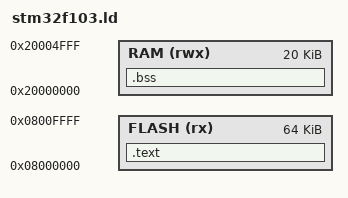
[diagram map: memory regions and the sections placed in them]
MEMORY
{
    FLASH (rx)  : ORIGIN = 0x08000000, LENGTH = 64K
    RAM   (rwx) : ORIGIN = 0x20000000, LENGTH = 20K
}
SECTIONS
{
    .text :
    {
        *(.isr_vector)
        *(.text)
        *(.rodata)
    } > FLASH

    .bss :
    {
        __bss_start__ = .;
        *(.bss)
        __bss_end__ = .;
        end = .;
    } > RAM
}
